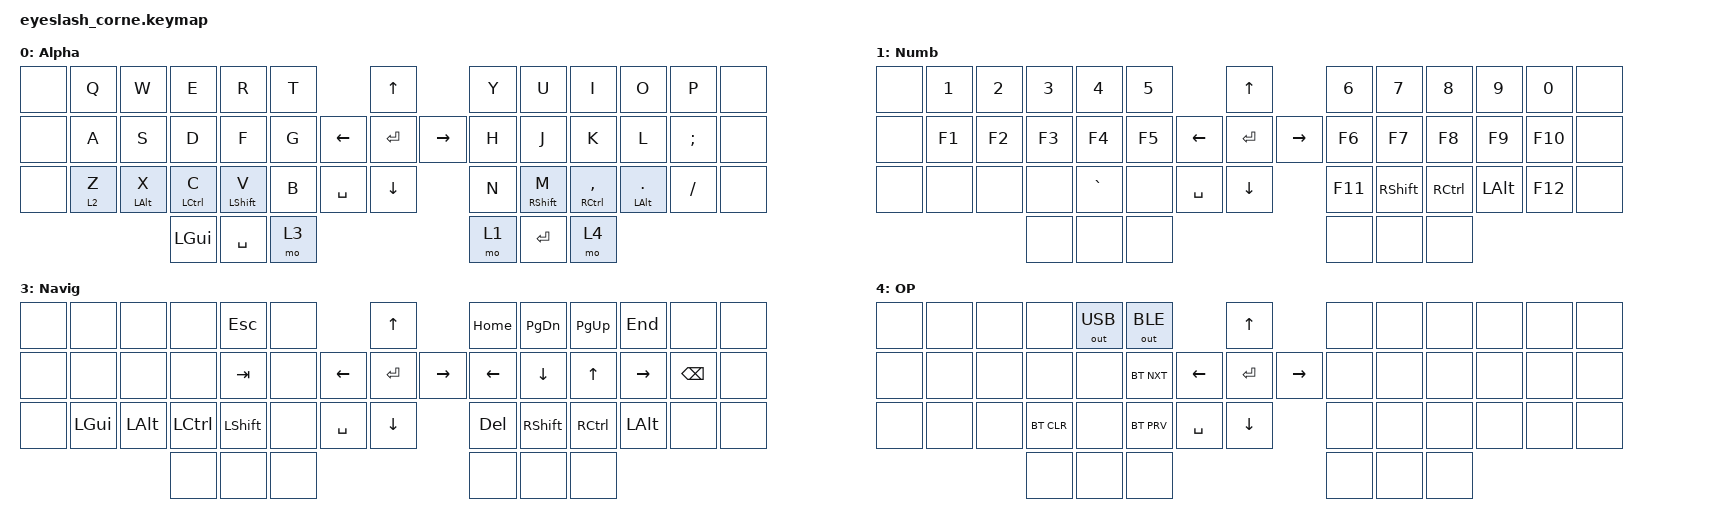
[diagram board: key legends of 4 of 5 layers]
#define ZMK_POINTING_DEFAULT_MOVE_VAL 1200  // 600
#define ZMK_POINTING_DEFAULT_SCRL_VAL 25   // 10

#include <input/processors.dtsi>
#include <zephyr/dt-bindings/input/input-event-codes.h>
#include <behaviors.dtsi>
#include <dt-bindings/zmk/bt.h>
#include <dt-bindings/zmk/ext_power.h>
#include <dt-bindings/zmk/keys.h>
#include <dt-bindings/zmk/pointing.h>
#include <dt-bindings/zmk/outputs.h>
#include <dt-bindings/zmk/rgb.h>
#include <behaviors/runtime-sensor-rotate.dtsi>

&mmv_input_listener { input-processors = <&zip_xy_scaler 2 1>; };

&msc_input_listener { input-processors = <&zip_scroll_scaler 2 1>; };

&msc {
    acceleration-exponent = <1>;      // 0
    time-to-max-speed-ms = <100>;       // 300
    delay-ms = <0>;                   // 0
};

&mmv {
    time-to-max-speed-ms = <500>;
    acceleration-exponent = <1>;
    trigger-period-ms = <16>;
};


/ {
    behaviors {
        rsr_vol: rsr_vol {
            compatible = "zmk,behavior-runtime-sensor-rotate";
            #sensor-binding-cells = <0>;
            tap-ms = <5>;
            cw-binding = <&kp C_VOL_UP>;
            ccw-binding = <&kp C_VOL_DN>;
        };

        rsr_trans: rsr_trans {
            compatible = "zmk,behavior-runtime-sensor-rotate";
            #sensor-binding-cells = <0>;
            tap-ms = <0>;
        };

        hml: home_row_mod_left {
            display-name = "hml";
            compatible = "zmk,behavior-hold-tap";
            #binding-cells = <2>;
            flavor = "balanced";
            require-prior-idle-ms = <150>;
            tapping-term-ms = <200>;
            quick-tap-ms = <175>;
            bindings = <&kp>, <&kp>;
            hold-trigger-key-positions = < 
                7	8	9	10	11	12
                22	23	24	25	26	27
                36	37	38	39	40	41
                45	46	47	
            >; // List of keys on the right side of the keyboard, optimized for key 43(v)
            hold-trigger-on-release;
        };
        hmr: home_row_mod_right {
            display-name = "hmr";
            compatible = "zmk,behavior-hold-tap";
            #binding-cells = <2>;
            flavor = "balanced";
            require-prior-idle-ms = <150>;
            tapping-term-ms = <200>;
            quick-tap-ms = <175>;
            bindings = <&kp>, <&kp>;
            hold-trigger-key-positions = <
                0	1	2	3	4	5
                13	14	15	16	17	18
                28	29	30	31	32	33
                            42	43	44	
            >; // List of keys on the left side of the keyboard
            hold-trigger-on-release;
        };
    };

    combos {
        compatible = "zmk,combos";

        combo_caps_word {
            timeout-ms = <50>;
            key-positions = <44 45>;
            bindings = <&caps_word>;
        };
    };   

    rgb_encoder: rgb_encoder {
        compatible = "zmk,behavior-sensor-rotate";
        #sensor-binding-cells = <0>;
        bindings = <&rgb_ug RGB_BRI>, <&rgb_ug RGB_BRD>;
    };

    scroll_encoder: scroll_encoder {
        compatible = "zmk,behavior-sensor-rotate";
        #sensor-binding-cells = <0>;
        bindings = <&msc SCRL_DOWN>, <&msc SCRL_UP>;
        tap-ms = <100>;
    };

    keymap {
        compatible = "zmk,keymap";

        Alpha {
            display-name = "Alpha";
            bindings = <
//|------------------|------------------|------------------|------------------|------------------|------------------|------------------|------------------|------------------|------------------|------------------|------------------|------------------|------------------|------------------
   &none              &kp Q              &kp W              &kp E              &kp R              &kp T                                 &kp UP                                &kp Y              &kp U              &kp I              &kp O              &kp P              &none
//|------------------|------------------|------------------|------------------|------------------|-----------r------|------------------|------------------|------------------|------------------|------------------|------------------|------------------|------------------|------------------
   &none              &kp A              &kp S              &kp D              &kp F              &kp G              &kp LEFT           &kp ENTER          &kp RIGHT          &kp H              &kp J              &kp K              &kp L              &kp SEMI           &none
//|------------------|------------------|------------------|------------------|------------------|------------------|------------------|------------------|------------------|------------------|------------------|------------------|------------------|------------------|------------------
   &none              &lt 2 Z            &hml LALT X        &hml LCTRL C       &hml LSHFT V       &kp B              &kp SPACE          &kp DOWN                              &kp N              &hmr RSHFT M       &hmr RCTRL COMMA   &hmr LALT DOT      &kp FSLH           &none
//|------------------|------------------|------------------|------------------|------------------|------------------|------------------|------------------|------------------|------------------|------------------|------------------|------------------|------------------|------------------
                                                            &kp LGUI           &kp SPACE          &mo 3                                                                       &mo 1              &kp ENTER          &mo 4                                      
//|------------------|------------------|------------------|------------------|------------------|------------------|------------------|------------------|------------------|------------------|------------------|------------------|------------------|------------------|------------------
            >;
            sensor-bindings = <&rsr_vol &rsr_trans>;
        };

        Number {
            display-name = "Numb";
            bindings = <
//|------------------|------------------|------------------|------------------|------------------|------------------|------------------|------------------|------------------|------------------|------------------|------------------|------------------|------------------|------------------
   &none              &kp N1             &kp N2             &kp N3             &kp N4             &kp N5                                &kp UP                                &kp N6             &kp N7             &kp N8             &kp N9             &kp N0             &none
//|------------------|------------------|------------------|------------------|------------------|------------------|------------------|------------------|------------------|------------------|------------------|------------------|------------------|------------------|------------------
   &none              &kp F1             &kp F2             &kp F3             &kp F4             &kp F5             &kp LEFT           &kp ENTER          &kp RIGHT          &kp F6             &kp F7             &kp F8             &kp F9             &kp F10            &none
//|------------------|------------------|------------------|------------------|------------------|------------------|------------------|------------------|------------------|------------------|------------------|------------------|------------------|------------------|------------------
   &none              &none              &none              &none              &kp GRAVE          &none              &kp SPACE          &kp DOWN                              &kp F11            &kp RSHFT          &kp RCTRL          &kp LALT           &kp F12            &none                  
//|------------------|------------------|------------------|------------------|------------------|------------------|------------------|------------------|------------------|------------------|------------------|------------------|------------------|------------------|------------------
                                                            &none              &none              &none                                                                       &none              &none              &none            
//|------------------|------------------|------------------|------------------|------------------|------------------|------------------|------------------|------------------|------------------|------------------|------------------|------------------|------------------|------------------
            >;
            sensor-bindings = <&rsr_vol &rsr_trans>;
        };

        Symbol {
            display-name = "Symb";
            bindings = <
//|------------------|------------------|------------------|------------------|------------------|------------------|------------------|------------------|------------------|------------------|------------------|------------------|------------------|------------------|------------------
   &none              &kp N1             &kp N2             &kp N3             &kp N4             &kp N5                                &kp UP                                &kp N6             &kp N7             &kp N8             &kp N9             &kp N0             &none
//|------------------|------------------|------------------|------------------|------------------|------------------|------------------|------------------|------------------|------------------|------------------|------------------|------------------|------------------|------------------
   &none              &none              &none              &none              &kp PSCRN          &none              &kp LEFT           &kp ENTER          &kp RIGHT          &kp MINUS          &kp EQUAL          &kp LBKT           &kp RBKT           &kp SEMI           &none            
//|------------------|------------------|------------------|------------------|------------------|------------------|------------------|------------------|------------------|------------------|------------------|------------------|------------------|------------------|------------------
   &none              &none              &kp LALT           &kp LCTRL          &kp LSHFT          &none              &kp SPACE          &kp DOWN                              &kp BSLH           &kp APOS           &kp COMMA          &kp DOT            &kp FSLH           &none            
//|------------------|------------------|------------------|------------------|------------------|------------------|------------------|------------------|------------------|------------------|------------------|------------------|------------------|------------------|------------------
   &none              &none              &none              &none              &none              &none                                                                       &none              &none              &none              &none              &none            
//|------------------|------------------|------------------|------------------|------------------|------------------|------------------|------------------|------------------|------------------|------------------|------------------|------------------|------------------|------------------
            >;
            sensor-bindings = <&scroll_encoder>;
        };

        Navigation {
            display-name = "Navig";
            bindings = <
//|------------------|------------------|------------------|------------------|------------------|------------------|------------------|------------------|------------------|------------------|------------------|------------------|------------------|------------------|------------------
   &none              &none              &none              &none              &kp ESC            &none                                 &kp UP                                &kp HOME           &kp PG_DN          &kp PG_UP          &kp END            &none              &none            
//|------------------|------------------|------------------|------------------|------------------|------------------|------------------|------------------|------------------|------------------|------------------|------------------|------------------|------------------|------------------
   &none              &none              &none              &none              &kp TAB            &none              &kp LEFT           &kp ENTER          &kp RIGHT          &kp LEFT           &kp DOWN           &kp UP             &kp RIGHT          &kp BACKSPACE      &none            
//|------------------|------------------|------------------|------------------|------------------|------------------|------------------|------------------|------------------|------------------|------------------|------------------|------------------|------------------|------------------
   &none              &kp LGUI           &kp LALT           &kp LCTRL          &kp LSHFT          &none              &kp SPACE          &kp DOWN                              &kp DEL            &kp RSHFT          &kp RCTRL          &kp LALT           &none              &none            
//|------------------|------------------|------------------|------------------|------------------|------------------|------------------|------------------|------------------|------------------|------------------|------------------|------------------|------------------|------------------
                                                            &none              &none              &none                                                                       &none              &none              &none                                                  
//|------------------|------------------|------------------|------------------|------------------|------------------|------------------|------------------|------------------|------------------|------------------|------------------|------------------|------------------|------------------
            >;
            sensor-bindings = <&rsr_vol &rsr_trans>;
        };

        Output {
            display-name = "OP";
            bindings = <
//|------------------|------------------|------------------|------------------|------------------|------------------|------------------|------------------|------------------|------------------|------------------|------------------|------------------|------------------|------------------
   &none              &none              &none              &none              &out OUT_USB       &out OUT_BLE                          &kp UP                                &none              &none              &none              &none              &none              &none            
//|------------------|------------------|------------------|------------------|------------------|------------------|------------------|------------------|------------------|------------------|------------------|------------------|------------------|------------------|------------------
   &none              &none              &none              &none              &none              &bt BT_NXT         &kp LEFT           &kp ENTER          &kp RIGHT          &none              &none              &none              &none              &none              &none            
//|------------------|------------------|------------------|------------------|------------------|------------------|------------------|------------------|------------------|------------------|------------------|------------------|------------------|------------------|------------------
   &none              &none              &none              &bt BT_CLR         &none              &bt BT_PRV         &kp SPACE          &kp DOWN                              &none              &none              &none              &none              &none              &none            
//|------------------|------------------|------------------|------------------|------------------|------------------|------------------|------------------|------------------|------------------|------------------|------------------|------------------|------------------|------------------
                                                            &none              &none              &none                                                                       &none              &none              &none                                                  
//|------------------|------------------|------------------|------------------|------------------|------------------|------------------|------------------|------------------|------------------|------------------|------------------|------------------|------------------|------------------
            >;
            sensor-bindings = <&rsr_vol &rsr_trans>;
        };
    };
};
